# M462 register map
File version: 0.1
Registers are 32-bit, read-write, reset 0x0 unless marked. A register's access mark holds for its fields unless they carry their own. Offsets are from the block's base; [hi:lo] are bit positions; {n}, {i} and the like mark numbered series.

## PG — Port G
Base 0x402C0600
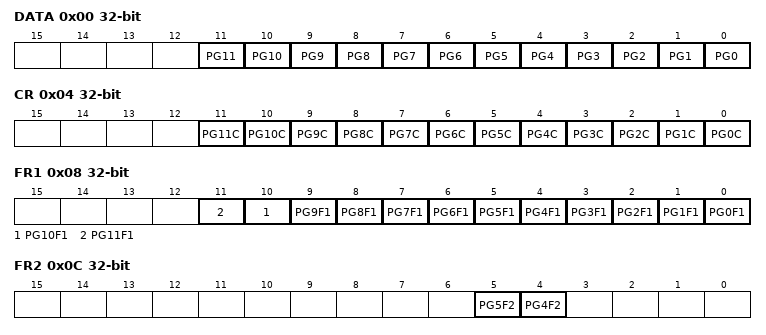
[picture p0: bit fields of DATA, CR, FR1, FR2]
0x00 DATA — Port G Data Register
  [n] PG{n} (n=0..11)
0x04 CR — Port G Output Control Register
  [n] PG{n}C (n=0..11)
0x08 FR1 — Port G Function Register 1
  [n] PG{n}F1 (n=0..11)
0x0C FR2 — Port G Function Register 2
  [5] PG5F2, [4] PG4F2
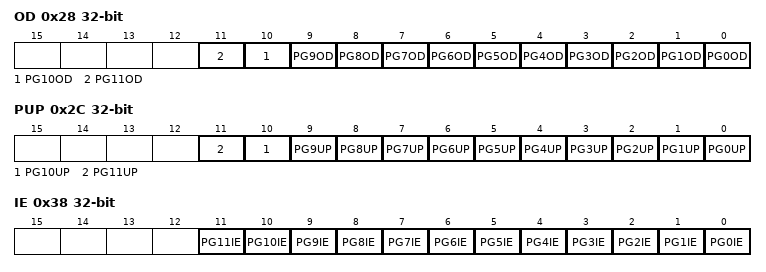
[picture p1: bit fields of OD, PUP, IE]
0x28 OD — Port G Open Drain Control Register
  [n] PG{n}OD (n=0..11)
0x2C PUP — Port G Pull-up Control Register
  [n] PG{n}UP (n=0..11)
0x38 IE — Port G Input Control Register
  [n] PG{n}IE (n=0..11)

## PH — Port H
Base 0x402C0700
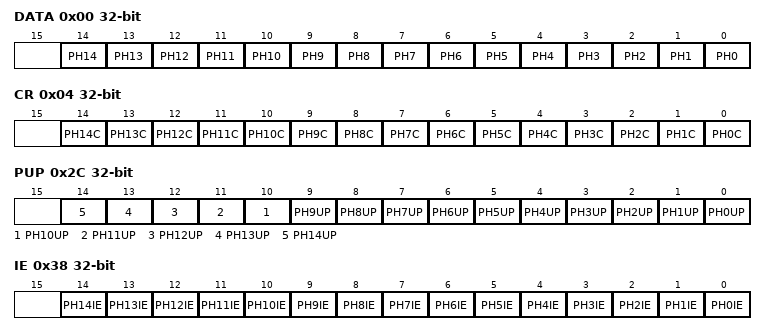
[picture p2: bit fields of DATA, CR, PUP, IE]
0x00 DATA — Port H Data Register
  [n] PH{n} (n=0..14)
0x04 CR — Port H Output Control Register
  [n] PH{n}C (n=0..14)
0x2C PUP — Port H Pull-up Control Register
  [n] PH{n}UP (n=0..14)
0x38 IE — Port H Input Control Register
  [n] PH{n}IE (n=0..14)

## PJ — Port J
Base 0x402C0800
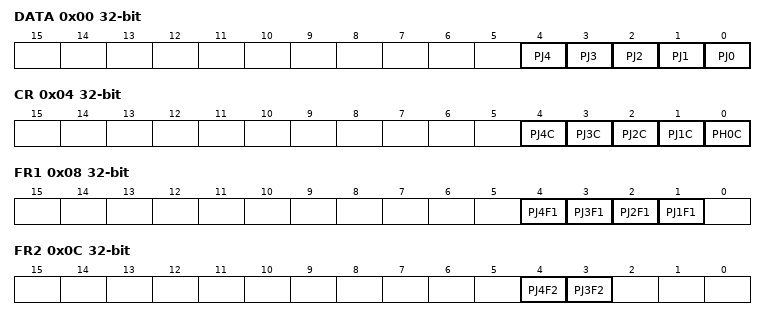
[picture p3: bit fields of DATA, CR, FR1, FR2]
0x00 DATA — Port J Data Register
  [n] PJ{n} (n=0..4)
0x04 CR — Port J Output Control Register
  [n] PJ{n}C (n=1..4), [0] PH0C
0x08 FR1 — Port J Function Register 1
  [n] PJ{n}F1 (n=1..4)
0x0C FR2 — Port J Function Register 2
  [4] PJ4F2, [3] PJ3F2
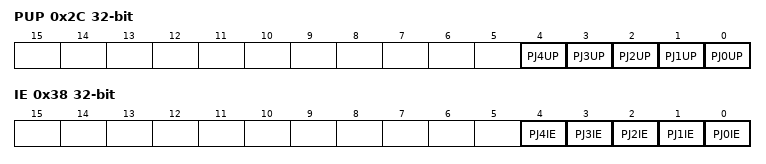
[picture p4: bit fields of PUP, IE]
0x2C PUP — Port J Pull-up Control Register
  [n] PJ{n}UP (n=0..4)
0x38 IE — Port J Input Control Register
  [n] PJ{n}IE (n=0..4)

## PK — Port K
Base 0x402C0900
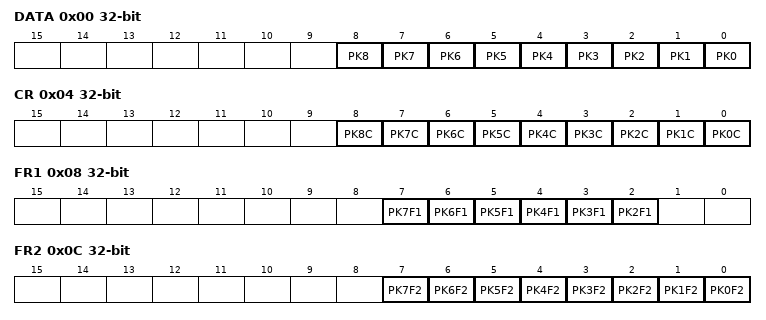
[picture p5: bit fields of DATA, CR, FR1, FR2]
0x00 DATA — Port K Data Register
  [n] PK{n} (n=0..8)
0x04 CR — Port K Output Control Register
  [n] PK{n}C (n=0..8)
0x08 FR1 — Port K Function Register 1
  [n] PK{n}F1 (n=2..7)
0x0C FR2 — Port K Function Register 2
  [n] PK{n}F2 (n=0..7)
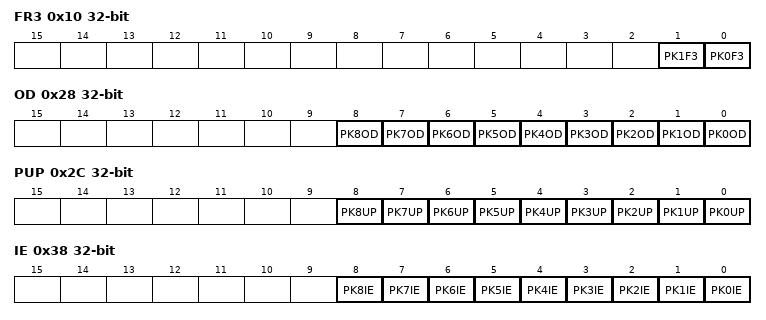
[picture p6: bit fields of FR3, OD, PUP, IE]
0x10 FR3 — Port K Function Register 3
  [1] PK1F3, [0] PK0F3
0x28 OD — Port K Open Drain Control Register
  [n] PK{n}OD (n=0..8)
0x2C PUP — Port K Pull-up Control Register
  [n] PK{n}UP (n=0..8)
0x38 IE — Port K Input Control Register
  [n] PK{n}IE (n=0..8)

## PL — Port L
Base 0x402C0A00
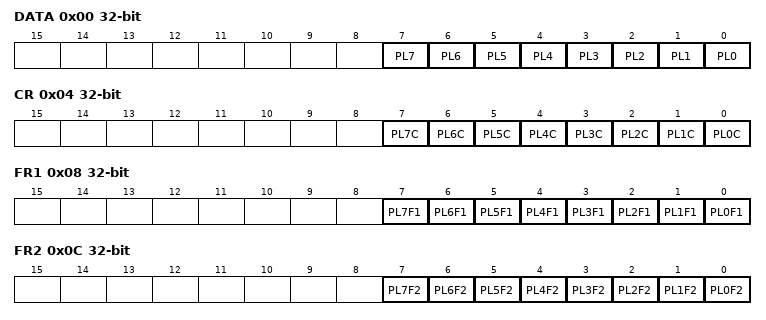
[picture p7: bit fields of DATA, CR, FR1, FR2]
0x00 DATA — Port L Data Register
  [n] PL{n} (n=0..7)
0x04 CR — Port L Output Control Register
  [n] PL{n}C (n=0..7)
0x08 FR1 — Port L Function Register 1
  [n] PL{n}F1 (n=0..7)
0x0C FR2 — Port L Function Register 2
  [n] PL{n}F2 (n=0..7)
0x10 FR3 — Port L Function Register 3
  [2] PL2F3
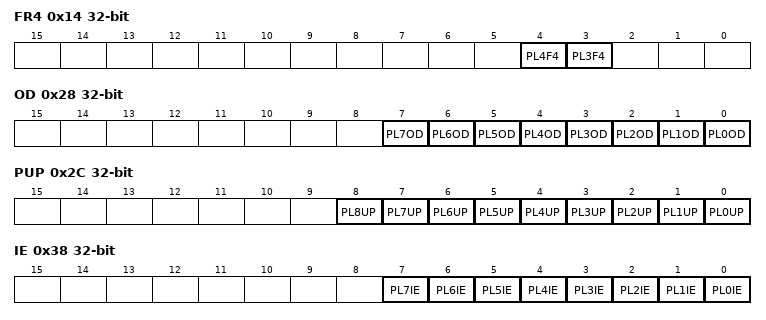
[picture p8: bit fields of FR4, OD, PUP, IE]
0x14 FR4 — Port L Function Register 4
  [4] PL4F4, [3] PL3F4
0x28 OD — Port L Open Drain Control Register
  [n] PL{n}OD (n=0..7)
0x2C PUP — Port L Pull-up Control Register
  [n] PL{n}UP (n=0..8)
0x38 IE — Port L Input Control Register
  [n] PL{n}IE (n=0..7)

## PM — Port M
Base 0x402C0B00
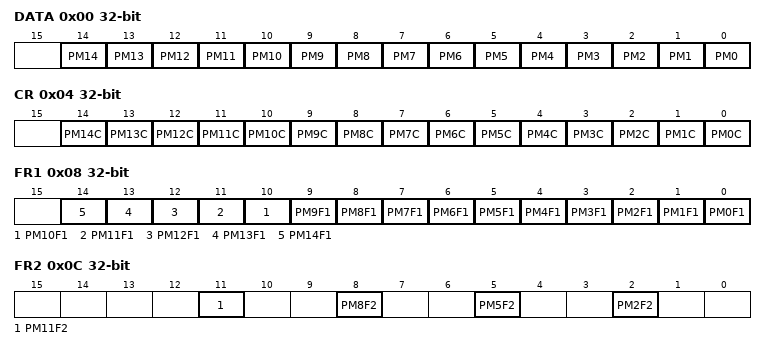
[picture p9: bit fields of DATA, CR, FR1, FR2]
0x00 DATA — Port M Data Register
  [n] PM{n} (n=0..14)
0x04 CR — Port M Output Control Register
  [n] PM{n}C (n=0..14)
0x08 FR1 — Port M Function Register 1
  [n] PM{n}F1 (n=0..14)
0x0C FR2 — Port M Function Register 2
  [11] PM11F2, [8] PM8F2, [5] PM5F2, [2] PM2F2
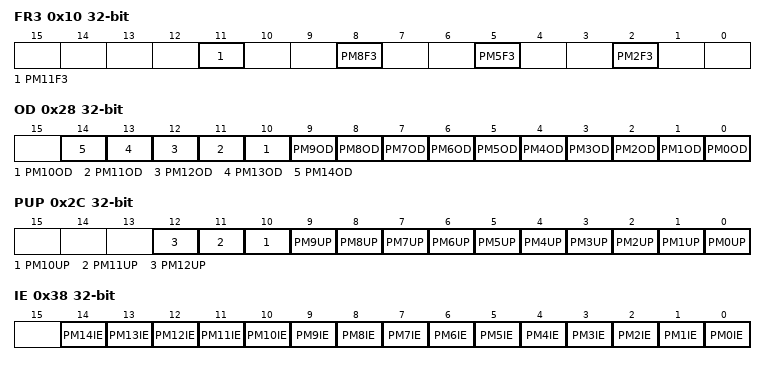
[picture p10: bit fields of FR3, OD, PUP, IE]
0x10 FR3 — Port M Function Register 3
  [11] PM11F3, [8] PM8F3, [5] PM5F3, [2] PM2F3
0x28 OD — Port M Open Drain Register
  [n] PM{n}OD (n=0..14)
0x2C PUP — Port M Pull-up Control Register
  [n] PM{n}UP (n=0..12)
0x38 IE — Port M Input Control Register
  [n] PM{n}IE (n=0..14)

## PN — Port N
Base 0x402C0C00
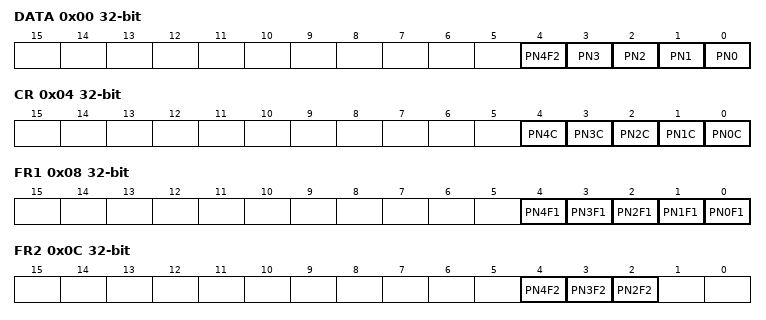
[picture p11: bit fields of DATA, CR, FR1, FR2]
0x00 DATA — Port N Data Register
  [4] PN4F2, [n] PN{n} (n=0..3)
0x04 CR — Port N Output Control Register
  [n] PN{n}C (n=0..4)
0x08 FR1 — Port N Function Register 1
  [n] PN{n}F1 (n=0..4)
0x0C FR2 — Port N Function Register 2
  [4] PN4F2, [3] PN3F2, [2] PN2F2
0x10 FR3 — Port N Function Register 3
  [4] PN4F3
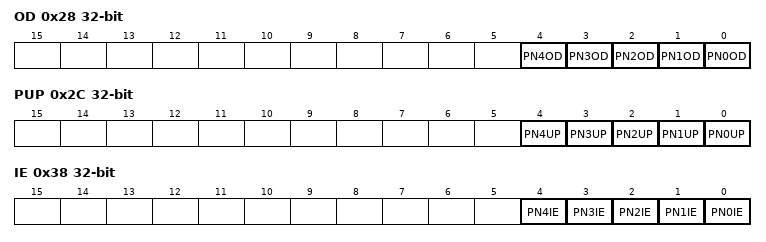
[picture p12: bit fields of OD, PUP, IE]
0x28 OD — Port N Open Drain Register
  [n] PN{n}OD (n=0..4)
0x2C PUP — Port N Pull-up Control Register
  [n] PN{n}UP (n=0..4)
0x38 IE — Port N Input Control Register
  [n] PN{n}IE (n=0..4)

## MT0 — 16-bit Multi-Purpose Timer (MPT-TMR_IGBT)
Base 0x402C7000
Same registers: MT1 0x402C7100
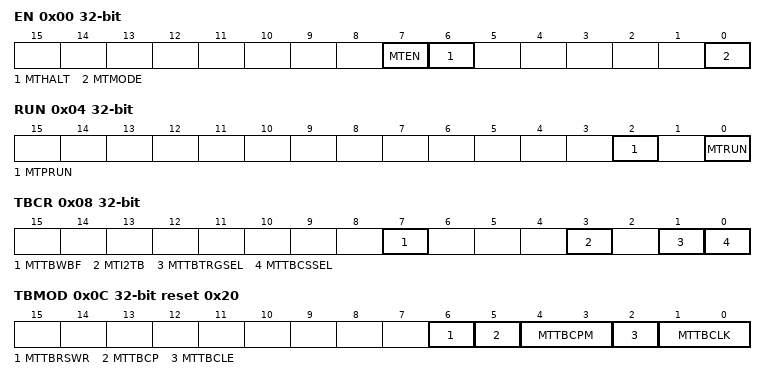
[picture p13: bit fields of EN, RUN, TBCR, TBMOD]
0x00 EN — MPT Enable Register
  [7] MTEN, [6] MTHALT, [0] MTMODE
0x04 RUN — MPT RUN Register
  [2] MTPRUN, [0] MTRUN
0x08 TBCR — MPT Control Register
  [7] MTTBWBF, [3] MTI2TB, [1] MTTBTRGSEL, [0] MTTBCSSEL
0x0C TBMOD reset 0x20 — MPT Mode Register
  [6] MTTBRSWR, [5] MTTBCP wo, [4:3] MTTBCPM, [2] MTTBCLE, [1:0] MTTBCLK
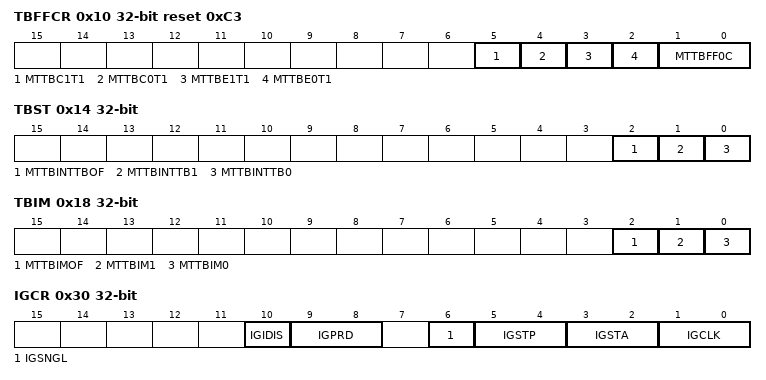
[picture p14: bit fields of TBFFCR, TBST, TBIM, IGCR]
0x10 TBFFCR reset 0xC3 — MPT Flip-Flop Control Register
  [5] MTTBC1T1, [4] MTTBC0T1, [3] MTTBE1T1, [2] MTTBE0T1, [1:0] MTTBFF0C
0x14 TBST ro — MPT Status Register
  [2] MTTBINTTBOF, [1] MTTBINTTB1, [0] MTTBINTTB0
0x18 TBIM — MPT Interrupt Mask Register
  [2] MTTBIMOF, [1] MTTBIM1, [0] MTTBIM0
0x1C TBUC ro — MPT Read Capture Register
  [15:0] MTUC
0x20 RG0 — MPT RG0 Timer Register
  [15:0] MTRG0
0x24 RG1 — MPT RG1 Timer Register
  [15:0] MTRG1
0x28 CP0 ro — MPT CP0 Capture Register
  [15:0] MTCP0
0x2C CP1 ro — MPT CP1 Capture Register
  [15:0] MTCP1
0x30 IGCR — IGBT Control Register
  [10] IGIDIS, [9:8] IGPRD, [6] IGSNGL, [5:4] IGSTP, [3:2] IGSTA, [1:0] IGCLK
0x34 IGRESTA wo — IGBT Timer Restart Register
  [0] IGRESTA
0x38 IGST ro — IGBT Timer Status Register
  [0] IGST
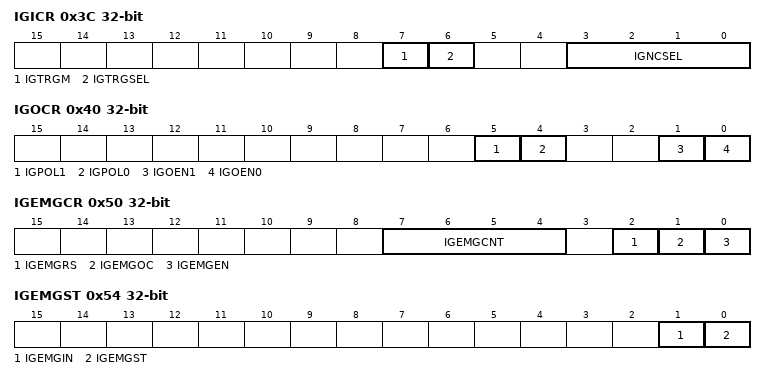
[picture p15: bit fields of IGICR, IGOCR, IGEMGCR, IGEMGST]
0x3C IGICR — IGBT Input Control Register
  [7] IGTRGM, [6] IGTRGSEL, [3:0] IGNCSEL
0x40 IGOCR — IGBT Output Control Register
  [5] IGPOL1, [4] IGPOL0, [1] IGOEN1, [0] IGOEN0
{0x3C+4i} IGRG{i} (i=2..4) — IGBT RG{i} Timer Register
  [15:0] IGRG{i}
0x50 IGEMGCR — IGBT EMG Control Register
  [7:4] IGEMGCNT, [2] IGEMGRS wo, [1] IGEMGOC, [0] IGEMGEN
0x54 IGEMGST ro — IGBT EMG Status Register
  [1] IGEMGIN, [0] IGEMGST
0x58 IGTRG — IGBT Trigger Status Register
  [15:0] IGTRG
